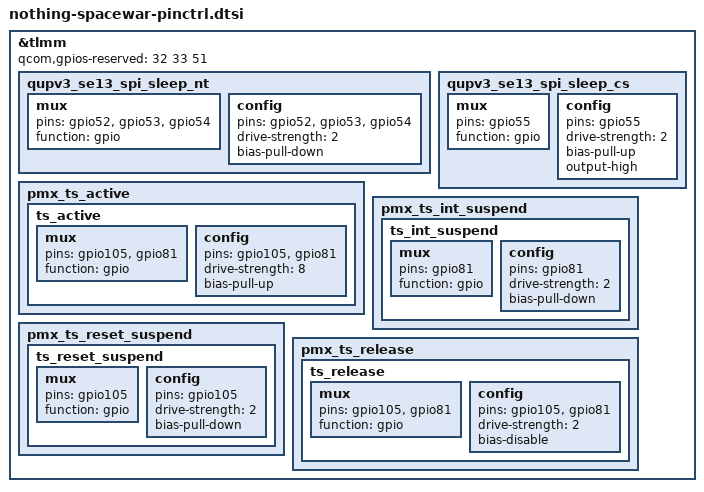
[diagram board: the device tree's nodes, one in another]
&tlmm {
	qcom,gpios-reserved = <32 33 51>;

	qupv3_se13_spi_sleep_nt: qupv3_se13_spi_sleep_nt {
		mux {
			pins = "gpio52", "gpio53", "gpio54";
			function = "gpio";
		};
		config {
			pins = "gpio52", "gpio53", "gpio54";
			drive-strength = <2>;
			bias-pull-down;
		};
	};

	qupv3_se13_spi_sleep_cs: qupv3_se13_spi_sleep_cs {
		mux {
			pins = "gpio55";
			function = "gpio";
		};
		config {
			pins = "gpio55";
			drive-strength = <2>;
			bias-pull-up;
			output-high;
		};
	};

	pmx_ts_active {
		ts_active: ts_active {
			mux {
				pins = "gpio105", "gpio81";
				function = "gpio";
			};
			config {
				pins = "gpio105", "gpio81";
				drive-strength = <8>;
				bias-pull-up;
			};
		};
	};

	pmx_ts_int_suspend {
		ts_int_suspend: ts_int_suspend {
			mux {
				pins = "gpio81";
				function = "gpio";
			};
			config {
				pins = "gpio81";
				drive-strength = <2>;
				bias-pull-down;
			};
		};
	};

	pmx_ts_reset_suspend {
		ts_reset_suspend: ts_reset_suspend {
			mux {
				pins = "gpio105";
				function = "gpio";
			};
			config {
				pins = "gpio105";
				drive-strength = <2>;
				bias-pull-down;
			};
		};
	};

	pmx_ts_release {
		ts_release: ts_release {
			mux {
				pins = "gpio105", "gpio81";
				function = "gpio";
			};
			config {
				pins = "gpio105", "gpio81";
				drive-strength = <2>;
				bias-disable;
			};
		};
	};
};
